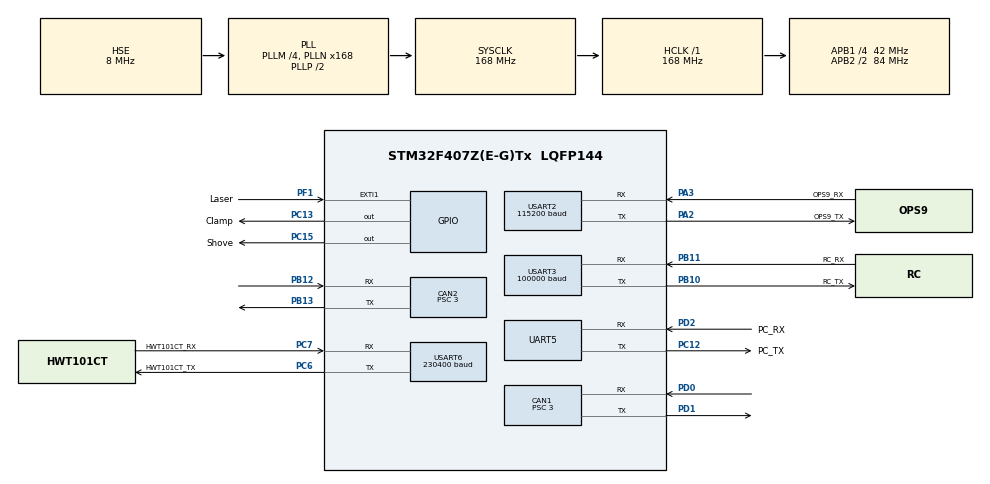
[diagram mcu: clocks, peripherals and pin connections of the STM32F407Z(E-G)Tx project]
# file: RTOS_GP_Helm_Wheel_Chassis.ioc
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CAN1.BS1=CAN_BS1_7TQ
CAN1.BS2=CAN_BS2_6TQ
CAN1.CalculateBaudRate=1000000
CAN1.CalculateTimeBit=1000
CAN1.CalculateTimeQuantum=71.42857142857143
CAN1.Prescaler=3
CAN2.BS1=CAN_BS1_10TQ
CAN2.BS2=CAN_BS2_3TQ
CAN2.CalculateBaudRate=1000000
CAN2.CalculateTimeBit=1000
CAN2.CalculateTimeQuantum=71.42857142857143
CAN2.Prescaler=3
Dma.Request0=USART3_RX
Dma.USART3_RX.0.Direction=DMA_PERIPH_TO_MEMORY
Dma.USART3_RX.0.FIFOMode=DMA_FIFOMODE_DISABLE
Dma.USART3_RX.0.Instance=DMA1_Stream1
Dma.USART3_RX.0.MemDataAlignment=DMA_MDATAALIGN_BYTE
Dma.USART3_RX.0.MemInc=DMA_MINC_ENABLE
Dma.USART3_RX.0.Mode=DMA_NORMAL
Dma.USART3_RX.0.PeriphDataAlignment=DMA_PDATAALIGN_BYTE
Dma.USART3_RX.0.PeriphInc=DMA_PINC_DISABLE
Dma.USART3_RX.0.Priority=DMA_PRIORITY_VERY_HIGH
FREERTOS.BinarySemaphores01=PC_BinarySem,Dynamic,NULL;CP_Link_BinarySem,Dynamic,NULL;Pneumatic_BinarySem,Dynamic,NULL
FREERTOS.INCLUDE_vTaskDelayUntil=1
FREERTOS.Queues01=Catch_Target_Queue,32,fp32,0,Dynamic,NULL,NULL;Push_Go_Queue,32,fp32,0,Dynamic,NULL,NULL;Push_Origin_Queue,32,fp32,0,Dynamic,NULL,NULL;Catch_Pre_Queue,32,fp32,0,Dynamic,NULL,NULL
FREERTOS.Tasks01=CHASSIS,0,128,chassis_task,As weak,NULL,Dynamic,NULL,NULL;OPS_RESET,0,128,ops_reset_task,As weak,NULL,Dynamic,NULL,NULL;CATCH,0,128,catch_task,As weak,NULL,Dynamic,NULL,NULL;PUSH,0,128,push_task,As weak,NULL,Dynamic,NULL,NULL;SHOOT,0,128,shoot_task,As weak,NULL,Dynamic,NULL,NULL;CAN2_CMD,0,128,can2_cmd_task,As weak,NULL,Dynamic,NULL,NULL;PNEUMATIC,0,128,pneumatic_task,As weak,NULL,Dynamic,NULL,NULL
Mcu.Family=STM32F4
Mcu.Name=STM32F407Z(E-G)Tx
Mcu.Package=LQFP144
NVIC.CAN1_RX0_IRQn=true\:5\:0\:false\:false\:true\:true\:true\:true\:true
NVIC.CAN2_RX0_IRQn=true\:5\:0\:false\:false\:true\:true\:true\:true\:true
NVIC.DMA1_Stream1_IRQn=true\:5\:0\:false\:false\:true\:true\:false\:true\:true
NVIC.EXTI1_IRQn=true\:5\:0\:false\:false\:true\:true\:true\:true\:true
NVIC.PriorityGroup=NVIC_PRIORITYGROUP_4
NVIC.TIM6_DAC_IRQn=true\:15\:0\:false\:false\:true\:false\:false\:true\:true
NVIC.TimeBase=TIM6_DAC_IRQn
NVIC.TimeBaseIP=TIM6
NVIC.UART5_IRQn=true\:5\:0\:false\:false\:true\:true\:true\:true\:true
NVIC.USART2_IRQn=true\:5\:0\:false\:false\:true\:true\:true\:true\:true
NVIC.USART3_IRQn=true\:5\:0\:false\:false\:true\:true\:true\:true\:true
NVIC.USART6_IRQn=true\:5\:0\:false\:false\:true\:true\:true\:true\:true
PA13.Mode=Serial_Wire
PA13.Signal=SYS_JTMS-SWDIO
PA14.Mode=Serial_Wire
PA14.Signal=SYS_JTCK-SWCLK
PA2.GPIO_Label=OPS9_TX
PA2.Mode=Asynchronous
PA2.Signal=USART2_TX
PA3.GPIO_Label=OPS9_RX
PA3.Mode=Asynchronous
PA3.Signal=USART2_RX
PB10.GPIO_Label=RC_TX
PB10.Mode=Asynchronous
PB10.Signal=USART3_TX
PB11.GPIO_Label=RC_RX
PB11.Mode=Asynchronous
PB11.Signal=USART3_RX
PB12.Mode=CAN_Activate
PB12.Signal=CAN2_RX
PB13.Mode=CAN_Activate
PB13.Signal=CAN2_TX
PC12.GPIO_Label=PC_TX
PC12.Mode=Asynchronous
PC12.Signal=UART5_TX
PC13-ANTI_TAMP.GPIO_Label=Clamp
PC13-ANTI_TAMP.Signal=GPIO_Output
PC15-OSC32_OUT.GPIO_Label=Shove
PC15-OSC32_OUT.Signal=GPIO_Output
PC6.GPIO_Label=HWT101CT_TX
PC6.Mode=Asynchronous
PC6.Signal=USART6_TX
PC7.GPIO_Label=HWT101CT_RX
PC7.Mode=Asynchronous
PC7.Signal=USART6_RX
PD0.Mode=CAN_Activate
PD0.Signal=CAN1_RX
PD1.Mode=CAN_Activate
PD1.Signal=CAN1_TX
PD2.GPIO_Label=PC_RX
PD2.Mode=Asynchronous
PD2.Signal=UART5_RX
PF1.GPIO_Label=Laser
PF1.Signal=GPXTI1
PH0-OSC_IN.Mode=HSE-External-Oscillator
PH0-OSC_IN.Signal=RCC_OSC_IN
PH1-OSC_OUT.Mode=HSE-External-Oscillator
PH1-OSC_OUT.Signal=RCC_OSC_OUT
ProjectManager.HeapSize=0x200
ProjectManager.StackSize=0x400
ProjectManager.TargetToolchain=MDK-ARM V5.32
RCC.48MHZClocksFreq_Value=84000000
RCC.AHBFreq_Value=168000000
RCC.APB1CLKDivider=RCC_HCLK_DIV4
RCC.APB1Freq_Value=42000000
RCC.APB1TimFreq_Value=84000000
RCC.APB2CLKDivider=RCC_HCLK_DIV2
RCC.APB2Freq_Value=84000000
RCC.APB2TimFreq_Value=168000000
RCC.CortexFreq_Value=168000000
RCC.HCLKFreq_Value=168000000
RCC.HSE_VALUE=8000000
RCC.HSI_VALUE=16000000
RCC.LSE_VALUE=32768
RCC.PLLM=4
RCC.PLLN=168
RCC.PLLSourceVirtual=RCC_PLLSOURCE_HSE
RCC.SYSCLKFreq_VALUE=168000000
RCC.SYSCLKSource=RCC_SYSCLKSOURCE_PLLCLK
RCC.VCOOutputFreq_Value=336000000
TIM14.Period=20000-1
TIM14.Prescaler=84-1
UART5.VirtualMode=Asynchronous
USART2.BaudRate=115200
USART2.VirtualMode=VM_ASYNC
USART3.BaudRate=100000
USART3.Mode=MODE_RX
USART3.Parity=PARITY_EVEN
USART3.VirtualMode=VM_ASYNC
USART6.BaudRate=230400
USART6.VirtualMode=VM_ASYNC
VP_FREERTOS_VS_CMSIS_V1.Mode=CMSIS_V1
VP_SYS_VS_tim6.Mode=TIM6
VP_TIM14_VS_ClockSourceINT.Mode=Enable_Timer
board=custom

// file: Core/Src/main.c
/* USER CODE BEGIN Header */
/**
  ******************************************************************************
  * @file           : main.c
  * @brief          : Main program body
  ******************************************************************************
  * @attention
  *
  * Copyright (c) 2023 STMicroelectronics.
  * All rights reserved.
  *
  * This software is licensed under terms that can be found in the LICENSE file
  * in the root directory of this software component.
  * If no LICENSE file comes with this software, it is provided AS-IS.
  *
  ******************************************************************************
  */
/* USER CODE END Header */
#include "main.h"
#include "cmsis_os.h"
#include "can.h"
#include "dma.h"
#include "tim.h"
#include "usart.h"
#include "gpio.h"

/* USER CODE BEGIN Includes */
#include "hwt101ct_232.h"
/* USER CODE END Includes */

void SystemClock_Config(void);
void MX_FREERTOS_Init(void);

/* USER CODE BEGIN 0 */
extern uint8_t rx_buffer[44];
extern uint8_t ops9_buffer[1];
extern uint8_t bluetooth_rx[1];
/* USER CODE END 0 */

int main(void)
{

  /* MCU Configuration--------------------------------------------------------*/

  /* Reset of all peripherals, Initializes the Flash interface and the Systick. */
  HAL_Init();

  /* Configure the system clock */
  SystemClock_Config();

  /* Initialize all configured peripherals */
  MX_GPIO_Init();
  MX_DMA_Init();
  MX_CAN1_Init();
  MX_CAN2_Init();
  MX_USART3_UART_Init();
  MX_USART2_UART_Init();
  MX_USART6_UART_Init();
  MX_TIM14_Init();
  MX_UART5_Init();
  /* USER CODE BEGIN 2 */
	remote_control_init();
	CAN_Start(&hcan1);
	CAN_Start(&hcan2);

	CAN1_Filter_Init();
	CAN2_Filter_Init();

//	IMU_Zero(&huart2);
	HAL_TIM_PWM_Start(&htim14,TIM_CHANNEL_1);

	HAL_UART_Receive_IT(&huart2,ops9_buffer,1);
	HAL_UART_Receive_IT(&huart6,rx_buffer,44);
//	HAL_UART_Receive_IT(&huart5,bluetooth_rx,1);
//	HAL_UART_Receive_DMA(&huart2,ops9_buffer,1);
//  HAL_UART_Receive_DMA(&huart6,rx_buffer,44);
  /* USER CODE END 2 */

  /* Call init function for freertos objects (in freertos.c) */
  MX_FREERTOS_Init();

  /* Start scheduler */
  osKernelStart();
  /* We should never get here as control is now taken by the scheduler */
  /* Infinite loop */
  while (1)
  {

  }
}

void SystemClock_Config(void)
{
  RCC_OscInitTypeDef RCC_OscInitStruct = {0};
  RCC_ClkInitTypeDef RCC_ClkInitStruct = {0};

  /** Configure the main internal regulator output voltage
  */
  __HAL_RCC_PWR_CLK_ENABLE();
  __HAL_PWR_VOLTAGESCALING_CONFIG(PWR_REGULATOR_VOLTAGE_SCALE1);

  /** Initializes the RCC Oscillators according to the specified parameters
  * in the RCC_OscInitTypeDef structure.
  */
  RCC_OscInitStruct.OscillatorType = RCC_OSCILLATORTYPE_HSE;
  RCC_OscInitStruct.HSEState = RCC_HSE_ON;
  RCC_OscInitStruct.PLL.PLLState = RCC_PLL_ON;
  RCC_OscInitStruct.PLL.PLLSource = RCC_PLLSOURCE_HSE;
  RCC_OscInitStruct.PLL.PLLM = 4;
  RCC_OscInitStruct.PLL.PLLN = 168;
  RCC_OscInitStruct.PLL.PLLP = RCC_PLLP_DIV2;
  RCC_OscInitStruct.PLL.PLLQ = 4;
  if (HAL_RCC_OscConfig(&RCC_OscInitStruct) != HAL_OK)
  {
    Error_Handler();
  }

  /** Initializes the CPU, AHB and APB buses clocks
  */
  RCC_ClkInitStruct.ClockType = RCC_CLOCKTYPE_HCLK|RCC_CLOCKTYPE_SYSCLK
                              |RCC_CLOCKTYPE_PCLK1|RCC_CLOCKTYPE_PCLK2;
  RCC_ClkInitStruct.SYSCLKSource = RCC_SYSCLKSOURCE_PLLCLK;
  RCC_ClkInitStruct.AHBCLKDivider = RCC_SYSCLK_DIV1;
  RCC_ClkInitStruct.APB1CLKDivider = RCC_HCLK_DIV4;
  RCC_ClkInitStruct.APB2CLKDivider = RCC_HCLK_DIV2;

  if (HAL_RCC_ClockConfig(&RCC_ClkInitStruct, FLASH_LATENCY_5) != HAL_OK)
  {
    Error_Handler();
  }
}

void HAL_TIM_PeriodElapsedCallback(TIM_HandleTypeDef *htim)
{
  if (htim->Instance == TIM6) {
    HAL_IncTick();
  }
}

void Error_Handler(void)
{
  __disable_irq();
  while (1)
  {
  }
}

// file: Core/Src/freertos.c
/* USER CODE BEGIN Header */
/**
  ******************************************************************************
  * File Name          : freertos.c
  * Description        : Code for freertos applications
  ******************************************************************************
  * @attention
  *
  * Copyright (c) 2023 STMicroelectronics.
  * All rights reserved.
  *
  * This software is licensed under terms that can be found in the LICENSE file
  * in the root directory of this software component.
  * If no LICENSE file comes with this software, it is provided AS-IS.
  *
  ******************************************************************************
  */
/* USER CODE END Header */

#include "FreeRTOS.h"
#include "task.h"
#include "main.h"
#include "cmsis_os.h"

osThreadId CHASSISHandle;
osThreadId OPS_RESETHandle;
osThreadId CATCHHandle;
osThreadId PUSHHandle;
osThreadId SHOOTHandle;
osThreadId CAN2_CMDHandle;
osThreadId PNEUMATICHandle;
osMessageQId Catch_Target_QueueHandle;
osMessageQId Push_Go_QueueHandle;
osMessageQId Push_Origin_QueueHandle;
osMessageQId Catch_Pre_QueueHandle;
osSemaphoreId PC_BinarySemHandle;
osSemaphoreId CP_Link_BinarySemHandle;
osSemaphoreId Pneumatic_BinarySemHandle;

void chassis_task(void const * argument);
void ops_reset_task(void const * argument);
void catch_task(void const * argument);
void push_task(void const * argument);
void shoot_task(void const * argument);
void can2_cmd_task(void const * argument);
void pneumatic_task(void const * argument);

void MX_FREERTOS_Init(void); /* (MISRA C 2004 rule 8.1) */

/* GetIdleTaskMemory prototype (linked to static allocation support) */
void vApplicationGetIdleTaskMemory( StaticTask_t **ppxIdleTaskTCBBuffer, StackType_t **ppxIdleTaskStackBuffer, uint32_t *pulIdleTaskStackSize );

/* USER CODE BEGIN GET_IDLE_TASK_MEMORY */
static StaticTask_t xIdleTaskTCBBuffer;
static StackType_t xIdleStack[configMINIMAL_STACK_SIZE];

void vApplicationGetIdleTaskMemory( StaticTask_t **ppxIdleTaskTCBBuffer, StackType_t **ppxIdleTaskStackBuffer, uint32_t *pulIdleTaskStackSize )
{
  *ppxIdleTaskTCBBuffer = &xIdleTaskTCBBuffer;
  *ppxIdleTaskStackBuffer = &xIdleStack[0];
  *pulIdleTaskStackSize = configMINIMAL_STACK_SIZE;
  /* place for user code */
}
/* USER CODE END GET_IDLE_TASK_MEMORY */

void MX_FREERTOS_Init(void) {

  /* Create the semaphores(s) */
  /* definition and creation of PC_BinarySem */
  osSemaphoreDef(PC_BinarySem);
  PC_BinarySemHandle = osSemaphoreCreate(osSemaphore(PC_BinarySem), 1);

  /* definition and creation of CP_Link_BinarySem */
  osSemaphoreDef(CP_Link_BinarySem);
  CP_Link_BinarySemHandle = osSemaphoreCreate(osSemaphore(CP_Link_BinarySem), 1);

  /* definition and creation of Pneumatic_BinarySem */
  osSemaphoreDef(Pneumatic_BinarySem);
  Pneumatic_BinarySemHandle = osSemaphoreCreate(osSemaphore(Pneumatic_BinarySem), 1);

  /* Create the queue(s) */
  /* definition and creation of Catch_Target_Queue */
  osMessageQDef(Catch_Target_Queue, 32, fp32);
  Catch_Target_QueueHandle = osMessageCreate(osMessageQ(Catch_Target_Queue), NULL);

  /* definition and creation of Push_Go_Queue */
  osMessageQDef(Push_Go_Queue, 32, fp32);
  Push_Go_QueueHandle = osMessageCreate(osMessageQ(Push_Go_Queue), NULL);

  /* definition and creation of Push_Origin_Queue */
  osMessageQDef(Push_Origin_Queue, 32, fp32);
  Push_Origin_QueueHandle = osMessageCreate(osMessageQ(Push_Origin_Queue), NULL);

  /* definition and creation of Catch_Pre_Queue */
  osMessageQDef(Catch_Pre_Queue, 32, fp32);
  Catch_Pre_QueueHandle = osMessageCreate(osMessageQ(Catch_Pre_Queue), NULL);

  /* Create the thread(s) */
  /* definition and creation of CHASSIS */
  osThreadDef(CHASSIS, chassis_task, osPriorityNormal, 0, 128);
  CHASSISHandle = osThreadCreate(osThread(CHASSIS), NULL);

  /* definition and creation of OPS_RESET */
  osThreadDef(OPS_RESET, ops_reset_task, osPriorityNormal, 0, 128);
  OPS_RESETHandle = osThreadCreate(osThread(OPS_RESET), NULL);

  /* definition and creation of CATCH */
  osThreadDef(CATCH, catch_task, osPriorityNormal, 0, 128);
  CATCHHandle = osThreadCreate(osThread(CATCH), NULL);

  /* definition and creation of PUSH */
  osThreadDef(PUSH, push_task, osPriorityNormal, 0, 128);
  PUSHHandle = osThreadCreate(osThread(PUSH), NULL);

  /* definition and creation of SHOOT */
  osThreadDef(SHOOT, shoot_task, osPriorityNormal, 0, 128);
  SHOOTHandle = osThreadCreate(osThread(SHOOT), NULL);

  /* definition and creation of CAN2_CMD */
  osThreadDef(CAN2_CMD, can2_cmd_task, osPriorityNormal, 0, 128);
  CAN2_CMDHandle = osThreadCreate(osThread(CAN2_CMD), NULL);

  /* definition and creation of PNEUMATIC */
  osThreadDef(PNEUMATIC, pneumatic_task, osPriorityNormal, 0, 128);
  PNEUMATICHandle = osThreadCreate(osThread(PNEUMATIC), NULL);

}

__weak void chassis_task(void const * argument)
{
  for(;;)
  {
    osDelay(1);
  }
}

__weak void ops_reset_task(void const * argument)
{
  for(;;)
  {
    osDelay(1);
  }
}

__weak void catch_task(void const * argument)
{
  for(;;)
  {
    osDelay(1);
  }
}

__weak void push_task(void const * argument)
{
  for(;;)
  {
    osDelay(1);
  }
}

__weak void shoot_task(void const * argument)
{
  for(;;)
  {
    osDelay(1);
  }
}

__weak void can2_cmd_task(void const * argument)
{
  for(;;)
  {
    osDelay(1);
  }
}

__weak void pneumatic_task(void const * argument)
{
  for(;;)
  {
    osDelay(1);
  }
}
